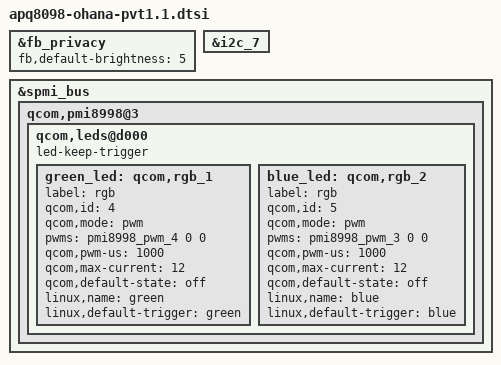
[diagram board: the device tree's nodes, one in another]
/* Copyright (c) 2018, Facebook Inc. All rights reserved.
 *
 * This program is free software; you can redistribute it and/or modify
 * it under the terms of the GNU General Public License version 2 and
 * only version 2 as published by the Free Software Foundation.
 *
 * This program is distributed in the hope that it will be useful,
 * but WITHOUT ANY WARRANTY; without even the implied warranty of
 * MERCHANTABILITY or FITNESS FOR A PARTICULAR PURPOSE.  See the
 * GNU General Public License for more details.
 */

#include "apq8098-ohana-evt1.1.dtsi"

&fb_privacy {
	fb,default-brightness = /bits/ 8 <5>;
};

&i2c_7 {
	/delete-node/ lp5521@32;
};

&spmi_bus {
	qcom,pmi8998@3 {
		qcom,leds@d000 {
			led-keep-trigger;

			green_led: qcom,rgb_1 {
				label = "rgb";
				qcom,id = <4>;
				qcom,mode = "pwm";
				pwms = <&pmi8998_pwm_4 0 0>;
				qcom,pwm-us = <1000>;
				qcom,max-current = <12>;
				qcom,default-state = "off";
				linux,name = "green";
				linux,default-trigger = "green";
			};

			blue_led: qcom,rgb_2 {
				label = "rgb";
				qcom,id = <5>;
				qcom,mode = "pwm";
				pwms = <&pmi8998_pwm_3 0 0>;
				qcom,pwm-us = <1000>;
				qcom,max-current = <12>;
				qcom,default-state = "off";
				linux,name = "blue";
				linux,default-trigger = "blue";
			};
		};
	};
};
